# TMC2209 register map
File version: 1.03
Step/Dir Drivers for Two-Phase Bipolar Stepper Motors up to 2.8A peak – StealthChop™ for Quiet Movement – UART Interface Option – Sensorless Stall Detection StallGuard4
Registers are 32-bit, read-write, reset 0x0 unless marked. A register's access mark holds for its fields unless they carry their own. Offsets are from the block's base; lines under a group give offsets from that group; [hi:lo] are bit positions; {n}, {i} and the like mark numbered series; 'fields as' and 'values as' point back to an identical list; <NAME> marks a mode.

## Memory map
0x00000000 General — General Registers
0x00000010 Velocity — VELOCITY DEPENDENT DRIVER FEATURE CONTROL REGISTER SET
0x00000014 StallGuard — COOLSTEP AND STALLGUARD CONTROL REGISTER SET
0x00000060 Sequencer — MICROSTEPPING CONTROL REGISTER SET
0x0000006C Chopper — Chopper Control Registers

## General — General Registers
Base 0x00000000
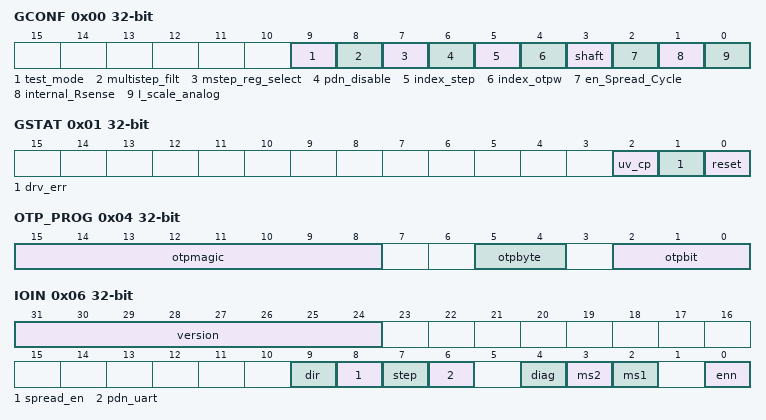
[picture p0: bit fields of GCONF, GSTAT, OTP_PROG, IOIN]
0x00 GCONF — GENERAL CONFIGURATION REGISTERS
  [9] test_mode, [8] multistep_filt, [7] mstep_reg_select, [6] pdn_disable, [5] index_step, [4] index_otpw, [3] shaft, [2] en_Spread_Cycle, [1] internal_Rsense, [0] I_scale_analog
0x01 GSTAT — Global status flags
  [2] uv_cp, [1] drv_err, [0] reset
0x02 IFCNT — Interface transmission counte
  [7:0] counter
0x03 SLAVECONF — SENDDELAY for read access (time until reply is sent)
  [11:8] send_delay
0x04 OTP_PROG — OTP_PROGRAM – OTP programming
  [15:8] otpmagic, [5:4] otpbyte, [2:0] otpbit
0x05 OTP_READ — OTP_READ (Access to OTP memory result and update)
  [23] otp_en_spread_cycle, [22:21] otp_ihold, [20:19] otp_ihold_delay, [18] otp_pwm_freq, [17] otp_pwm_reg, [16] otp_chopconf_8, [16] otp_pwm_ofs, [15:13] otp_chopconf_7_5, [15:13] otp_tpwmthrs, [12] otp_chopconf_4, [12] otp_pwm_autograd, [11:8] otp_chopconf_3_0, [11:8] otp_pwm_grad, [7] otp_tbl, [6] otp_internal_rsense, [5] otp_ottrim, [4:0] otp_fclktrim
0x06 IOIN — INPUT (Reads the state of all input pins available)
  [31:24] version, [9] dir, [8] spread_en, [7] step, [6] pdn_uart, [4] diag, [3] ms2, [2] ms1, [0] enn
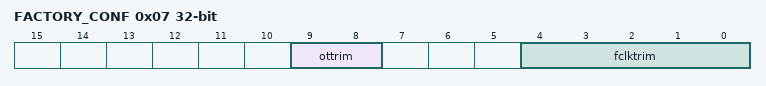
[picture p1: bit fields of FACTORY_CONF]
0x07 FACTORY_CONF — Factory config
  [9:8] ottrim, [4:0] fclktrim

## Velocity — VELOCITY DEPENDENT DRIVER FEATURE CONTROL REGISTER SET
Base 0x00000010
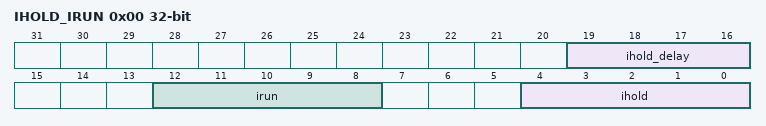
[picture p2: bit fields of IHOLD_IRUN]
0x00 IHOLD_IRUN — Driver current control
  [19:16] ihold_delay, [12:8] irun, [4:0] ihold
0x01 TPOWER_DOWN — Sets the delay time from stand still (stst) detection to motor current power down.
  [7:0] tpower_down_f
0x02 TSTEP — Actual measured time between two 1/256 microsteps derived from the step input frequency in units of 1/fCLK.
  [19:0] tstep_f
0x03 TPWMTHRS — Sets the upper velocity for StealthChop voltage PWM mode.
  [19:0] tpwmthrs_f
0x12 VACTUAL — VACTUAL allows moving the motor by UART control.
  [23:0] vactual_f

## StallGuard — COOLSTEP AND STALLGUARD CONTROL REGISTER SET
Base 0x00000014
0x00 TCOOLTHRS — This is the lower threshold velocity for switching on smart energy CoolStep and StallGuard to DIAG output.
  [19:0] tcoolthrs_f
0x2C SGTHRS — Detection threshold for stall.
  [7:0] sgthrs_f
0x2D SG_RESULT ro — StallGuard result.
  [9:0] sg_result_f
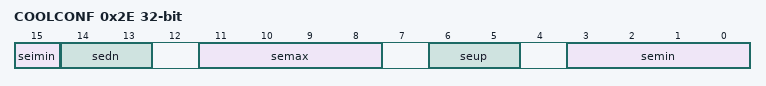
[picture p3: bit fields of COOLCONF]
0x2E COOLCONF wo — CoolStep configuration
  [15] seimin, [14:13] sedn, [11:8] semax, [6:5] seup, [3:0] semin

## Sequencer — MICROSTEPPING CONTROL REGISTER SET
Base 0x00000060
0x0A MSCNT ro — Microstep counter
  [9:0] mscnt_f
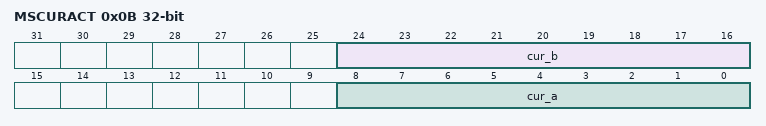
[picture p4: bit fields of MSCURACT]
0x0B MSCURACT ro — Actual microstep current
  [24:16] cur_b, [8:0] cur_a

## Chopper — Chopper Control Registers
Base 0x0000006C
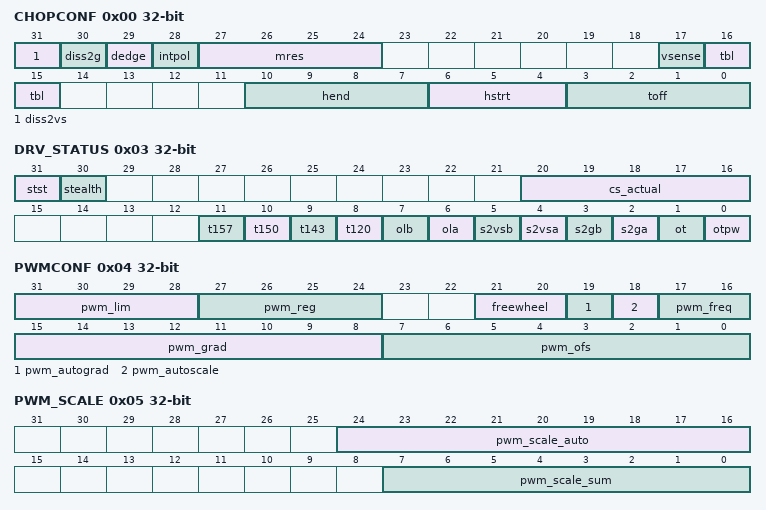
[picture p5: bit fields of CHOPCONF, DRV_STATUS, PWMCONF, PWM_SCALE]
0x00 CHOPCONF — Chopper and driver configuration
  [31] diss2vs, [30] diss2g, [29] dedge, [28] intpol, [27:24] mres, [17] vsense, [16:15] tbl, [10:7] hend, [6:4] hstrt, [3:0] toff
0x03 DRV_STATUS — Driver status flags and current level read back
  [31] stst, [30] stealth, [20:16] cs_actual, [11] t157, [10] t150, [9] t143, [8] t120, [7] olb, [6] ola, [5] s2vsb, [4] s2vsa, [3] s2gb, [2] s2ga, [1] ot, [0] otpw
0x04 PWMCONF — StealthChop PWM chopper configuration
  [31:28] pwm_lim, [27:24] pwm_reg, [21:20] freewheel, [19] pwm_autograd, [18] pwm_autoscale, [17:16] pwm_freq, [15:8] pwm_grad, [7:0] pwm_ofs
0x05 PWM_SCALE — Results of StealthChop amplitude regulator.
  [24:16] pwm_scale_auto, [7:0] pwm_scale_sum
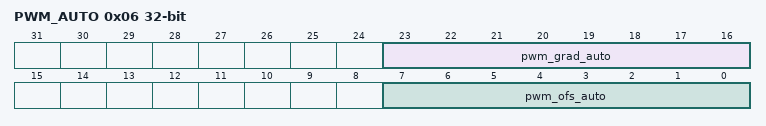
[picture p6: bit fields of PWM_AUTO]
0x06 PWM_AUTO — These automatically generated values can be read out in order to determine a default / power up setting for PWM_GRAD and PWM_OFS.
  [23:16] pwm_grad_auto, [7:0] pwm_ofs_auto
